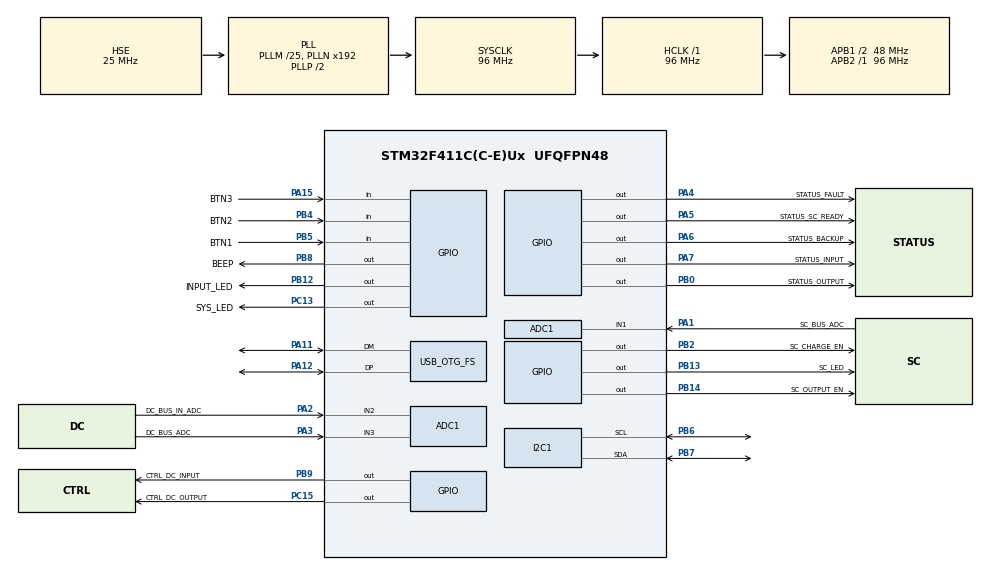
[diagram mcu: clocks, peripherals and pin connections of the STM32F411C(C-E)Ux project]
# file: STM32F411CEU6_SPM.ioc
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ADC1.Channel-0\#ChannelRegularConversion=ADC_CHANNEL_1
ADC1.NbrOfConversionFlag=1
ADC1.Rank-0\#ChannelRegularConversion=1
ADC1.SamplingTime-0\#ChannelRegularConversion=ADC_SAMPLETIME_84CYCLES
ADC1.master=1
FREERTOS.Tasks01=defaultTask,24,512,StartDefaultTask,Default,NULL,Dynamic,NULL,NULL
Mcu.Family=STM32F4
Mcu.Name=STM32F411C(C-E)Ux
Mcu.Package=UFQFPN48
NVIC.OTG_FS_IRQn=true\:5\:0\:false\:false\:true\:true\:false\:true\:true
NVIC.PriorityGroup=NVIC_PRIORITYGROUP_4
NVIC.TIM2_IRQn=true\:5\:0\:false\:false\:true\:true\:true\:true\:true
PA1.GPIO_Label=SC_BUS_ADC
PA1.Signal=ADCx_IN1
PA11.Mode=Device_Only
PA11.Signal=USB_OTG_FS_DM
PA12.Mode=Device_Only
PA12.Signal=USB_OTG_FS_DP
PA13.Mode=Serial_Wire
PA13.Signal=SYS_JTMS-SWDIO
PA14.Mode=Serial_Wire
PA14.Signal=SYS_JTCK-SWCLK
PA15.GPIO_Label=BTN3
PA15.Signal=GPIO_Input
PA2.GPIO_Label=DC_BUS_IN_ADC
PA2.Signal=ADCx_IN2
PA3.GPIO_Label=DC_BUS_ADC
PA3.Signal=ADCx_IN3
PA4.GPIO_Label=STATUS_FAULT
PA4.PinState=GPIO_PIN_RESET
PA4.Signal=GPIO_Output
PA5.GPIO_Label=STATUS_SC_READY
PA5.PinState=GPIO_PIN_RESET
PA5.Signal=GPIO_Output
PA6.GPIO_Label=STATUS_BACKUP
PA6.PinState=GPIO_PIN_RESET
PA6.Signal=GPIO_Output
PA7.GPIO_Label=STATUS_INPUT
PA7.PinState=GPIO_PIN_RESET
PA7.Signal=GPIO_Output
PB0.GPIO_Label=STATUS_OUTPUT
PB0.PinState=GPIO_PIN_RESET
PB0.Signal=GPIO_Output
PB12.GPIO_Label=INPUT_LED
PB12.PinState=GPIO_PIN_SET
PB12.Signal=GPIO_Output
PB13.GPIO_Label=SC_LED
PB13.PinState=GPIO_PIN_SET
PB13.Signal=GPIO_Output
PB14.GPIO_Label=SC_OUTPUT_EN
PB14.PinState=GPIO_PIN_RESET
PB14.Signal=GPIO_Output
PB2.GPIO_Label=SC_CHARGE_EN
PB2.PinState=GPIO_PIN_RESET
PB2.Signal=GPIO_Output
PB4.GPIO_Label=BTN2
PB4.Signal=GPIO_Input
PB5.GPIO_Label=BTN1
PB5.Signal=GPIO_Input
PB6.Mode=I2C
PB6.Signal=I2C1_SCL
PB7.Mode=I2C
PB7.Signal=I2C1_SDA
PB8.GPIO_Label=BEEP
PB8.PinState=GPIO_PIN_RESET
PB8.Signal=GPIO_Output
PB9.GPIO_Label=CTRL_DC_INPUT
PB9.PinState=GPIO_PIN_SET
PB9.Signal=GPIO_Output
PC13-ANTI_TAMP.GPIO_Label=SYS_LED
PC13-ANTI_TAMP.PinState=GPIO_PIN_SET
PC13-ANTI_TAMP.Signal=GPIO_Output
PC15-OSC32_OUT.GPIO_Label=CTRL_DC_OUTPUT
PC15-OSC32_OUT.PinState=GPIO_PIN_RESET
PC15-OSC32_OUT.Signal=GPIO_Output
PH0\ -\ OSC_IN.Mode=HSE-External-Oscillator
PH0\ -\ OSC_IN.Signal=RCC_OSC_IN
PH1\ -\ OSC_OUT.Mode=HSE-External-Oscillator
PH1\ -\ OSC_OUT.Signal=RCC_OSC_OUT
ProjectManager.HeapSize=0x200
ProjectManager.StackSize=0x400
ProjectManager.TargetToolchain=MDK-ARM V5.32
RCC.48MHZClocksFreq_Value=48000000
RCC.AHBFreq_Value=96000000
RCC.APB1CLKDivider=RCC_HCLK_DIV2
RCC.APB1Freq_Value=48000000
RCC.APB1TimFreq_Value=96000000
RCC.APB2Freq_Value=96000000
RCC.APB2TimFreq_Value=96000000
RCC.CortexFreq_Value=96000000
RCC.HCLKFreq_Value=96000000
RCC.HSE_VALUE=25000000
RCC.HSI_VALUE=16000000
RCC.LSE_VALUE=32768
RCC.PLLM=25
RCC.SYSCLKFreq_VALUE=96000000
RCC.SYSCLKSource=RCC_SYSCLKSOURCE_PLLCLK
RCC.VCOOutputFreq_Value=192000000
SH.ADCx_IN1.0=ADC1_IN1,IN1
SH.ADCx_IN2.0=ADC1_IN2,IN2
SH.ADCx_IN3.0=ADC1_IN3,IN3
TIM2.Period=99
TIM2.Prescaler=95
USB_DEVICE.CLASS_NAME_FS=CDC
USB_DEVICE.VirtualMode=Cdc
USB_DEVICE.VirtualModeFS=Cdc_FS
USB_OTG_FS.VirtualMode=Device_Only
VP_FREERTOS_VS_CMSIS_V2.Mode=CMSIS_V2
VP_TIM2_VS_ClockSourceINT.Mode=Internal
VP_USB_DEVICE_VS_USB_DEVICE_CDC_FS.Mode=CDC_FS
board=custom

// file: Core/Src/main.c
/* USER CODE BEGIN Header */
/**
  ******************************************************************************
  * @file           : main.c
  * @brief          : Main program body
  ******************************************************************************
  * @attention
  *
  * Copyright (c) 2026 STMicroelectronics.
  * All rights reserved.
  *
  * This software is licensed under terms that can be found in the LICENSE file
  * in the root directory of this software component.
  * If no LICENSE file comes with this software, it is provided AS-IS.
  *
  ******************************************************************************
  */
/* USER CODE END Header */
#include "main.h"
#include "cmsis_os.h"
#include "usb_device.h"

/* USER CODE BEGIN Includes */
#include "power_control.h"
#include "power_config.h"
/* USER CODE END Includes */

ADC_HandleTypeDef hadc1;

I2C_HandleTypeDef hi2c1;

TIM_HandleTypeDef htim2;

/* Definitions for defaultTask */
osThreadId_t defaultTaskHandle;
const osThreadAttr_t defaultTask_attributes = {
  .name = "defaultTask",
  .stack_size = 512 * 4,
  .priority = (osPriority_t) osPriorityNormal,
};

void SystemClock_Config(void);
static void MX_GPIO_Init(void);
static void MX_ADC1_Init(void);
static void MX_I2C1_Init(void);
static void MX_TIM2_Init(void);
void StartDefaultTask(void *argument);

int main(void)
{

  /* MCU Configuration--------------------------------------------------------*/

  /* Reset of all peripherals, Initializes the Flash interface and the Systick. */
  HAL_Init();

  /* Configure the system clock */
  SystemClock_Config();

  /* Initialize all configured peripherals */
  MX_GPIO_Init();
  MX_ADC1_Init();
  MX_I2C1_Init();
  MX_TIM2_Init();

  /* Init scheduler */
  osKernelInitialize();

  /* Create the thread(s) */
  /* creation of defaultTask */
  defaultTaskHandle = osThreadNew(StartDefaultTask, NULL, &defaultTask_attributes);

  /* Start scheduler */
  osKernelStart();

  /* We should never get here as control is now taken by the scheduler */

  /* Infinite loop */
  while (1)
  {

  }
}

void SystemClock_Config(void)
{
  RCC_OscInitTypeDef RCC_OscInitStruct = {0};
  RCC_ClkInitTypeDef RCC_ClkInitStruct = {0};

  /** Configure the main internal regulator output voltage
  */
  __HAL_RCC_PWR_CLK_ENABLE();
  __HAL_PWR_VOLTAGESCALING_CONFIG(PWR_REGULATOR_VOLTAGE_SCALE1);

  /** Initializes the RCC Oscillators according to the specified parameters
  * in the RCC_OscInitTypeDef structure.
  */
  RCC_OscInitStruct.OscillatorType = RCC_OSCILLATORTYPE_HSE;
  RCC_OscInitStruct.HSEState = RCC_HSE_ON;
  RCC_OscInitStruct.PLL.PLLState = RCC_PLL_ON;
  RCC_OscInitStruct.PLL.PLLSource = RCC_PLLSOURCE_HSE;
  RCC_OscInitStruct.PLL.PLLM = 25;
  RCC_OscInitStruct.PLL.PLLN = 192;
  RCC_OscInitStruct.PLL.PLLP = RCC_PLLP_DIV2;
  RCC_OscInitStruct.PLL.PLLQ = 4;
  if (HAL_RCC_OscConfig(&RCC_OscInitStruct) != HAL_OK)
  {
    Error_Handler();
  }

  /** Initializes the CPU, AHB and APB buses clocks
  */
  RCC_ClkInitStruct.ClockType = RCC_CLOCKTYPE_HCLK|RCC_CLOCKTYPE_SYSCLK
                              |RCC_CLOCKTYPE_PCLK1|RCC_CLOCKTYPE_PCLK2;
  RCC_ClkInitStruct.SYSCLKSource = RCC_SYSCLKSOURCE_PLLCLK;
  RCC_ClkInitStruct.AHBCLKDivider = RCC_SYSCLK_DIV1;
  RCC_ClkInitStruct.APB1CLKDivider = RCC_HCLK_DIV2;
  RCC_ClkInitStruct.APB2CLKDivider = RCC_HCLK_DIV1;

  if (HAL_RCC_ClockConfig(&RCC_ClkInitStruct, FLASH_LATENCY_3) != HAL_OK)
  {
    Error_Handler();
  }
}

static void MX_ADC1_Init(void)
{

  ADC_ChannelConfTypeDef sConfig = {0};

  /** Configure the global features of the ADC (Clock, Resolution, Data Alignment and number of conversion)
  */
  hadc1.Instance = ADC1;
  hadc1.Init.ClockPrescaler = ADC_CLOCK_SYNC_PCLK_DIV4;
  hadc1.Init.Resolution = ADC_RESOLUTION_12B;
  hadc1.Init.ScanConvMode = DISABLE;
  hadc1.Init.ContinuousConvMode = DISABLE;
  hadc1.Init.DiscontinuousConvMode = DISABLE;
  hadc1.Init.ExternalTrigConvEdge = ADC_EXTERNALTRIGCONVEDGE_NONE;
  hadc1.Init.ExternalTrigConv = ADC_SOFTWARE_START;
  hadc1.Init.DataAlign = ADC_DATAALIGN_RIGHT;
  hadc1.Init.NbrOfConversion = 1;
  hadc1.Init.DMAContinuousRequests = DISABLE;
  hadc1.Init.EOCSelection = ADC_EOC_SINGLE_CONV;
  if (HAL_ADC_Init(&hadc1) != HAL_OK)
  {
    Error_Handler();
  }

  /** Configure for the selected ADC regular channel its corresponding rank in the sequencer and its sample time.
  */
  sConfig.Channel = ADC_CHANNEL_1;
  sConfig.Rank = 1;
  sConfig.SamplingTime = ADC_SAMPLETIME_84CYCLES;
  if (HAL_ADC_ConfigChannel(&hadc1, &sConfig) != HAL_OK)
  {
    Error_Handler();
  }

}

static void MX_I2C1_Init(void)
{

  hi2c1.Instance = I2C1;
  hi2c1.Init.ClockSpeed = 100000;
  hi2c1.Init.DutyCycle = I2C_DUTYCYCLE_2;
  hi2c1.Init.OwnAddress1 = 0;
  hi2c1.Init.AddressingMode = I2C_ADDRESSINGMODE_7BIT;
  hi2c1.Init.DualAddressMode = I2C_DUALADDRESS_DISABLE;
  hi2c1.Init.OwnAddress2 = 0;
  hi2c1.Init.GeneralCallMode = I2C_GENERALCALL_DISABLE;
  hi2c1.Init.NoStretchMode = I2C_NOSTRETCH_DISABLE;
  if (HAL_I2C_Init(&hi2c1) != HAL_OK)
  {
    Error_Handler();
  }

}

static void MX_TIM2_Init(void)
{

  TIM_ClockConfigTypeDef sClockSourceConfig = {0};
  TIM_MasterConfigTypeDef sMasterConfig = {0};

  htim2.Instance = TIM2;
  htim2.Init.Prescaler = 95;
  htim2.Init.CounterMode = TIM_COUNTERMODE_UP;
  htim2.Init.Period = 99;
  htim2.Init.ClockDivision = TIM_CLOCKDIVISION_DIV1;
  htim2.Init.AutoReloadPreload = TIM_AUTORELOAD_PRELOAD_DISABLE;
  if (HAL_TIM_Base_Init(&htim2) != HAL_OK)
  {
    Error_Handler();
  }
  sClockSourceConfig.ClockSource = TIM_CLOCKSOURCE_INTERNAL;
  if (HAL_TIM_ConfigClockSource(&htim2, &sClockSourceConfig) != HAL_OK)
  {
    Error_Handler();
  }
  sMasterConfig.MasterOutputTrigger = TIM_TRGO_RESET;
  sMasterConfig.MasterSlaveMode = TIM_MASTERSLAVEMODE_DISABLE;
  if (HAL_TIMEx_MasterConfigSynchronization(&htim2, &sMasterConfig) != HAL_OK)
  {
    Error_Handler();
  }

}

static void MX_GPIO_Init(void)
{
  GPIO_InitTypeDef GPIO_InitStruct = {0};

  /* GPIO Ports Clock Enable */
  __HAL_RCC_GPIOC_CLK_ENABLE();
  __HAL_RCC_GPIOH_CLK_ENABLE();
  __HAL_RCC_GPIOA_CLK_ENABLE();
  __HAL_RCC_GPIOB_CLK_ENABLE();

  /*Configure GPIO pin Output Level */
  HAL_GPIO_WritePin(SYS_LED_GPIO_Port, SYS_LED_Pin, GPIO_PIN_SET);

  /*Configure GPIO pin Output Level */
  HAL_GPIO_WritePin(CTRL_DC_OUTPUT_GPIO_Port, CTRL_DC_OUTPUT_Pin, GPIO_PIN_RESET);

  /*Configure GPIO pin Output Level */
  HAL_GPIO_WritePin(GPIOA, STATUS_FAULT_Pin|STATUS_SC_READY_Pin|STATUS_BACKUP_Pin|STATUS_INPUT_Pin, GPIO_PIN_RESET);

  /*Configure GPIO pin Output Level */
  HAL_GPIO_WritePin(GPIOB, STATUS_OUTPUT_Pin|SC_CHARGE_EN_Pin|SC_OUTPUT_EN_Pin|BEEP_Pin, GPIO_PIN_RESET);

  /*Configure GPIO pin Output Level */
  HAL_GPIO_WritePin(GPIOB, INPUT_LED_Pin|SC_LED_Pin|CTRL_DC_INPUT_Pin, GPIO_PIN_SET);

  /*Configure GPIO pins : SYS_LED_Pin CTRL_DC_OUTPUT_Pin */
  GPIO_InitStruct.Pin = SYS_LED_Pin|CTRL_DC_OUTPUT_Pin;
  GPIO_InitStruct.Mode = GPIO_MODE_OUTPUT_PP;
  GPIO_InitStruct.Pull = GPIO_NOPULL;
  GPIO_InitStruct.Speed = GPIO_SPEED_FREQ_LOW;
  HAL_GPIO_Init(GPIOC, &GPIO_InitStruct);

  /*Configure GPIO pins : STATUS_FAULT_Pin STATUS_SC_READY_Pin STATUS_BACKUP_Pin STATUS_INPUT_Pin */
  GPIO_InitStruct.Pin = STATUS_FAULT_Pin|STATUS_SC_READY_Pin|STATUS_BACKUP_Pin|STATUS_INPUT_Pin;
  GPIO_InitStruct.Mode = GPIO_MODE_OUTPUT_PP;
  GPIO_InitStruct.Pull = GPIO_NOPULL;
  GPIO_InitStruct.Speed = GPIO_SPEED_FREQ_LOW;
  HAL_GPIO_Init(GPIOA, &GPIO_InitStruct);

  /*Configure GPIO pins : STATUS_OUTPUT_Pin SC_CHARGE_EN_Pin INPUT_LED_Pin SC_LED_Pin
                           SC_OUTPUT_EN_Pin BEEP_Pin CTRL_DC_INPUT_Pin */
  GPIO_InitStruct.Pin = STATUS_OUTPUT_Pin|SC_CHARGE_EN_Pin|INPUT_LED_Pin|SC_LED_Pin
                          |SC_OUTPUT_EN_Pin|BEEP_Pin|CTRL_DC_INPUT_Pin;
  GPIO_InitStruct.Mode = GPIO_MODE_OUTPUT_PP;
  GPIO_InitStruct.Pull = GPIO_NOPULL;
  GPIO_InitStruct.Speed = GPIO_SPEED_FREQ_LOW;
  HAL_GPIO_Init(GPIOB, &GPIO_InitStruct);

  /*Configure GPIO pin : BTN3_Pin */
  GPIO_InitStruct.Pin = BTN3_Pin;
  GPIO_InitStruct.Mode = GPIO_MODE_INPUT;
  GPIO_InitStruct.Pull = GPIO_NOPULL;
  HAL_GPIO_Init(BTN3_GPIO_Port, &GPIO_InitStruct);

  /*Configure GPIO pins : BTN2_Pin BTN1_Pin */
  GPIO_InitStruct.Pin = BTN2_Pin|BTN1_Pin;
  GPIO_InitStruct.Mode = GPIO_MODE_INPUT;
  GPIO_InitStruct.Pull = GPIO_NOPULL;
  HAL_GPIO_Init(GPIOB, &GPIO_InitStruct);

}

void StartDefaultTask(void *argument)
{
  /* init code for USB_DEVICE */
  MX_USB_DEVICE_Init();
  /* USER CODE BEGIN 5 */
  PowerControl_Init(&hadc1, &hi2c1, &htim2);
  /* Infinite loop */
  for(;;)
  {
    PowerControl_Run();
    osDelay(POWER_TASK_PERIOD_MS);
  }
  /* USER CODE END 5 */
}

void Error_Handler(void)
{
  __disable_irq();
  while (1)
  {
  }
}
